AUTOSAR XML (schema 4-0-3)
standard types defined: uint8, UInt8
package /AUTOSAR_Platform/DataConstrs
  range DC_UInt8: raw 0..255
package /PATAC/MSM/ComponentTypes
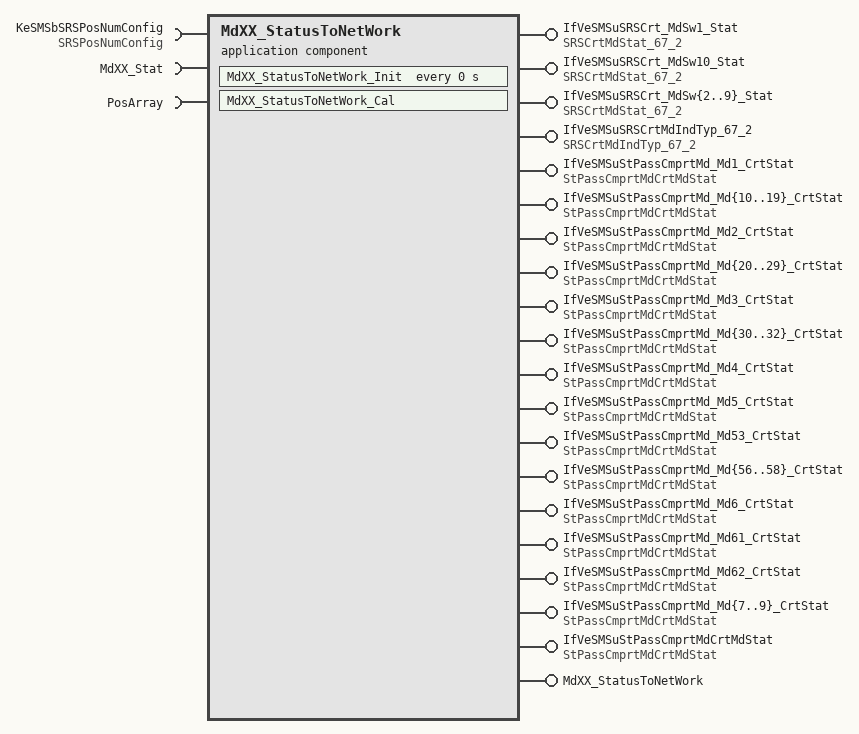
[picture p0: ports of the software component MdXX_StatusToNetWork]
  application sw component type MdXX_StatusToNetWork
    51 x provide port:
      IfVeSMSuSRSCrt_MdSw1_Stat: nonqueued-sender-com-spec{data-element=SRSCrtMdStat_67_2/Val, init-value=0}, provided-interface=SRSCrtMdStat_67_2
      IfVeSMSuSRSCrt_MdSw10_Stat: nonqueued-sender-com-spec{data-element=SRSCrtMdStat_67_2/Val, init-value=0}, provided-interface=SRSCrtMdStat_67_2
      IfVeSMSuSRSCrt_MdSw{2..9}_Stat: nonqueued-sender-com-spec{data-element=SRSCrtMdStat_67_2/Val, init-value=0}, provided-interface=SRSCrtMdStat_67_2
      IfVeSMSuSRSCrtMdIndTyp_67_2: nonqueued-sender-com-spec{data-element=SRSCrtMdIndTyp_67_2/Val, init-value=0}, provided-interface=SRSCrtMdIndTyp_67_2
      IfVeSMSuStPassCmprtMd_Md1_CrtStat: nonqueued-sender-com-spec{data-element=StPassCmprtMdCrtMdStat/Val, init-value=0}, provided-interface=StPassCmprtMdCrtMdStat
      IfVeSMSuStPassCmprtMd_Md{10..19}_CrtStat: nonqueued-sender-com-spec{data-element=StPassCmprtMdCrtMdStat/Val, init-value=0}, provided-interface=StPassCmprtMdCrtMdStat
      IfVeSMSuStPassCmprtMd_Md2_CrtStat: nonqueued-sender-com-spec{data-element=StPassCmprtMdCrtMdStat/Val, init-value=0}, provided-interface=StPassCmprtMdCrtMdStat
      IfVeSMSuStPassCmprtMd_Md{20..29}_CrtStat: nonqueued-sender-com-spec{data-element=StPassCmprtMdCrtMdStat/Val, init-value=0}, provided-interface=StPassCmprtMdCrtMdStat
      IfVeSMSuStPassCmprtMd_Md3_CrtStat: nonqueued-sender-com-spec{data-element=StPassCmprtMdCrtMdStat/Val, init-value=0}, provided-interface=StPassCmprtMdCrtMdStat
      IfVeSMSuStPassCmprtMd_Md{30..32}_CrtStat: nonqueued-sender-com-spec{data-element=StPassCmprtMdCrtMdStat/Val, init-value=0}, provided-interface=StPassCmprtMdCrtMdStat
      IfVeSMSuStPassCmprtMd_Md4_CrtStat: nonqueued-sender-com-spec{data-element=StPassCmprtMdCrtMdStat/Val, init-value=0}, provided-interface=StPassCmprtMdCrtMdStat
      IfVeSMSuStPassCmprtMd_Md5_CrtStat: nonqueued-sender-com-spec{data-element=StPassCmprtMdCrtMdStat/Val, init-value=0}, provided-interface=StPassCmprtMdCrtMdStat
      IfVeSMSuStPassCmprtMd_Md53_CrtStat: nonqueued-sender-com-spec{data-element=StPassCmprtMdCrtMdStat/Val, init-value=0}, provided-interface=StPassCmprtMdCrtMdStat
      IfVeSMSuStPassCmprtMd_Md{56..58}_CrtStat: nonqueued-sender-com-spec{data-element=StPassCmprtMdCrtMdStat/Val, init-value=0}, provided-interface=StPassCmprtMdCrtMdStat
      IfVeSMSuStPassCmprtMd_Md6_CrtStat: nonqueued-sender-com-spec{data-element=StPassCmprtMdCrtMdStat/Val, init-value=0}, provided-interface=StPassCmprtMdCrtMdStat
      IfVeSMSuStPassCmprtMd_Md61_CrtStat: nonqueued-sender-com-spec{data-element=StPassCmprtMdCrtMdStat/Val, init-value=0}, provided-interface=StPassCmprtMdCrtMdStat
      IfVeSMSuStPassCmprtMd_Md62_CrtStat: nonqueued-sender-com-spec{data-element=StPassCmprtMdCrtMdStat/Val, init-value=0}, provided-interface=StPassCmprtMdCrtMdStat
      IfVeSMSuStPassCmprtMd_Md{7..9}_CrtStat: nonqueued-sender-com-spec{data-element=StPassCmprtMdCrtMdStat/Val, init-value=0}, provided-interface=StPassCmprtMdCrtMdStat
      IfVeSMSuStPassCmprtMdCrtMdStat: nonqueued-sender-com-spec{data-element=StPassCmprtMdCrtMdStat/Val, init-value=0}, provided-interface=StPassCmprtMdCrtMdStat
      MdXX_StatusToNetWork: server-com-spec{operation=Cal, queue-length=1}, provided-interface=MdXX_StatusToNetWork
    require port KeSMSbSRSPosNumConfig: parameter-require-com-spec{init-value=4, parameter=Val}, required-interface=SRSPosNumConfig
    require port MdXX_Stat: required-interface=MdXX_Stat
      required-com-specs:
        data-element=Md1_Stat, filter=data-filter-type=ALWAYS, init-value=0
        data-element=Md{10..19}_Stat, filter=data-filter-type=ALWAYS, init-value=0
        data-element=Md2_Stat, filter=data-filter-type=ALWAYS, init-value=0
        data-element=Md{20..29}_Stat, filter=data-filter-type=ALWAYS, init-value=0
        data-element=Md3_Stat, filter=data-filter-type=ALWAYS, init-value=0
        data-element=Md{30..32}_Stat, filter=data-filter-type=ALWAYS, init-value=0
        data-element=Md{4..9}_Stat, filter=data-filter-type=ALWAYS, init-value=0
    require port PosArray: nonqueued-receiver-com-spec{data-element=PosArray/Val, filter=data-filter-type=ALWAYS, init-value=11 x 0}, required-interface=PosArray
    behavior MdXX_StatusToNetWork_InternalBehavior
      operation invoked event OIT_MdXX_StatusToNetWork_Cal_MdXX_StatusToNetWork_Cal: start-on-event=MdXX_StatusToNetWork_Cal, operation=MdXX_StatusToNetWork.Cal
      timing event MdXX_StatusToNetWork_InitEvent: start-on-event=MdXX_StatusToNetWork_Init, period=0
      runnable MdXX_StatusToNetWork_Cal
        data-receive-point-by-arguments:
          33 x access:
            REC_MdXX_Stat_Md1_Stat: accessed-variable=MdXX_Stat.Md1_Stat
            REC_MdXX_Stat_Md{10..19}_Stat: accessed-variable=MdXX_Stat.Md{10..19}_Stat
            REC_MdXX_Stat_Md2_Stat: accessed-variable=MdXX_Stat.Md2_Stat
            REC_MdXX_Stat_Md{20..29}_Stat: accessed-variable=MdXX_Stat.Md{20..29}_Stat
            REC_MdXX_Stat_Md3_Stat: accessed-variable=MdXX_Stat.Md3_Stat
            REC_MdXX_Stat_Md{30..32}_Stat: accessed-variable=MdXX_Stat.Md{30..32}_Stat
            REC_MdXX_Stat_Md{4..9}_Stat: accessed-variable=MdXX_Stat.Md{4..9}_Stat
            REC_PosArray_Val: accessed-variable=PosArray.Val
        data-send-points:
          50 x access:
            SEND_IfVeSMSuSRSCrt_MdSw1_Stat_Val: accessed-variable=IfVeSMSuSRSCrt_MdSw1_Stat.Val
            SEND_IfVeSMSuSRSCrt_MdSw10_Stat_Val: accessed-variable=IfVeSMSuSRSCrt_MdSw10_Stat.Val
            SEND_IfVeSMSuSRSCrt_MdSw{2..9}_Stat_Val: accessed-variable=IfVeSMSuSRSCrt_MdSw{2..9}_Stat.Val
            SEND_IfVeSMSuSRSCrtMdIndTyp_67_2_Val: accessed-variable=IfVeSMSuSRSCrtMdIndTyp_67_2.Val
            SEND_IfVeSMSuStPassCmprtMd_Md1_CrtStat_Val: accessed-variable=IfVeSMSuStPassCmprtMd_Md1_CrtStat.Val
            SEND_IfVeSMSuStPassCmprtMd_Md{10..19}_CrtStat_Val: accessed-variable=IfVeSMSuStPassCmprtMd_Md{10..19}_CrtStat.Val
            SEND_IfVeSMSuStPassCmprtMd_Md2_CrtStat_Val: accessed-variable=IfVeSMSuStPassCmprtMd_Md2_CrtStat.Val
            SEND_IfVeSMSuStPassCmprtMd_Md{20..29}_CrtStat_Val: accessed-variable=IfVeSMSuStPassCmprtMd_Md{20..29}_CrtStat.Val
            SEND_IfVeSMSuStPassCmprtMd_Md3_CrtStat_Val: accessed-variable=IfVeSMSuStPassCmprtMd_Md3_CrtStat.Val
            SEND_IfVeSMSuStPassCmprtMd_Md{30..32}_CrtStat_Val: accessed-variable=IfVeSMSuStPassCmprtMd_Md{30..32}_CrtStat.Val
            SEND_IfVeSMSuStPassCmprtMd_Md4_CrtStat_Val: accessed-variable=IfVeSMSuStPassCmprtMd_Md4_CrtStat.Val
            SEND_IfVeSMSuStPassCmprtMd_Md5_CrtStat_Val: accessed-variable=IfVeSMSuStPassCmprtMd_Md5_CrtStat.Val
            SEND_IfVeSMSuStPassCmprtMd_Md53_CrtStat_Val: accessed-variable=IfVeSMSuStPassCmprtMd_Md53_CrtStat.Val
            SEND_IfVeSMSuStPassCmprtMd_Md{56..58}_CrtStat_Val: accessed-variable=IfVeSMSuStPassCmprtMd_Md{56..58}_CrtStat.Val
            SEND_IfVeSMSuStPassCmprtMd_Md6_CrtStat_Val: accessed-variable=IfVeSMSuStPassCmprtMd_Md6_CrtStat.Val
            SEND_IfVeSMSuStPassCmprtMd_Md61_CrtStat_Val: accessed-variable=IfVeSMSuStPassCmprtMd_Md61_CrtStat.Val
            SEND_IfVeSMSuStPassCmprtMd_Md62_CrtStat_Val: accessed-variable=IfVeSMSuStPassCmprtMd_Md62_CrtStat.Val
            SEND_IfVeSMSuStPassCmprtMd_Md{7..9}_CrtStat_Val: accessed-variable=IfVeSMSuStPassCmprtMd_Md{7..9}_CrtStat.Val
            SEND_IfVeSMSuStPassCmprtMdCrtMdStat_Val: accessed-variable=IfVeSMSuStPassCmprtMdCrtMdStat.Val
        parameter access PA_KeSMSbSRSPosNumConfig_Val: accessed-parameter=KeSMSbSRSPosNumConfig.Val
      runnable MdXX_StatusToNetWork_Init
        parameter access PA_KeSMSbSRSPosNumConfig_Val: accessed-parameter=KeSMSbSRSPosNumConfig.Val
  swc implementation MdXX_StatusToNetWork_Implementation: behavior=MdXX_StatusToNetWork_InternalBehavior
    code-descriptors:
      code Default: artifact-descriptors=autosar-engineering-object={short-label=Default, category=SWSRC}
package /PATAC/MSM/ModeAdjust/CalPortInterface
  parameter interface SRSPosNumConfig
    parameter data prototype Val: sw-calibration-access=READ-WRITE, type=UInt8
package /PATAC/MSM/ModeAdjust/DataType
  impl type ModeList: category=ARRAY, sw-calibration-access=READ-ONLY, type-emitter=RTE
    element Val: array-size=11, array-size-semantics=FIXED-SIZE, implementation-data-type=UInt8
package /PATAC/MSM/ModeAdjust/PortInterface
  client server interface MdXX_StatusToNetWork
    operation Cal
  5 x sender receiver interface:
    MdXX_Stat
      32 x data, all with type=UInt8:
        Md1_Stat
        Md{10..19}_Stat
        Md2_Stat
        Md{20..29}_Stat
        Md3_Stat
        Md{30..32}_Stat
        Md{4..9}_Stat
      invalidation-policys:
        data-element=Md1_Stat, handle-invalid=DONT-INVALIDATE
        data-element=Md{10..19}_Stat, handle-invalid=DONT-INVALIDATE
        data-element=Md2_Stat, handle-invalid=DONT-INVALIDATE
        data-element=Md{20..29}_Stat, handle-invalid=DONT-INVALIDATE
        data-element=Md3_Stat, handle-invalid=DONT-INVALIDATE
        data-element=Md{30..32}_Stat, handle-invalid=DONT-INVALIDATE
        data-element=Md{4..9}_Stat, handle-invalid=DONT-INVALIDATE
    PosArray: invalidation-policy{data-element=PosArray/Val, handle-invalid=DONT-INVALIDATE}
      data Val: type=ModeList
    SRSCrtMdIndTyp_67_2: invalidation-policy{data-element=SRSCrtMdIndTyp_67_2/Val, handle-invalid=DONT-INVALIDATE}
      data Val: type=UInt8
    SRSCrtMdStat_67_2: invalidation-policy{data-element=SRSCrtMdStat_67_2/Val, handle-invalid=DONT-INVALIDATE}
      data Val: type=UInt8
    StPassCmprtMdCrtMdStat: invalidation-policy{data-element=StPassCmprtMdCrtMdStat/Val, handle-invalid=DONT-INVALIDATE}
      data Val: type=UInt8
